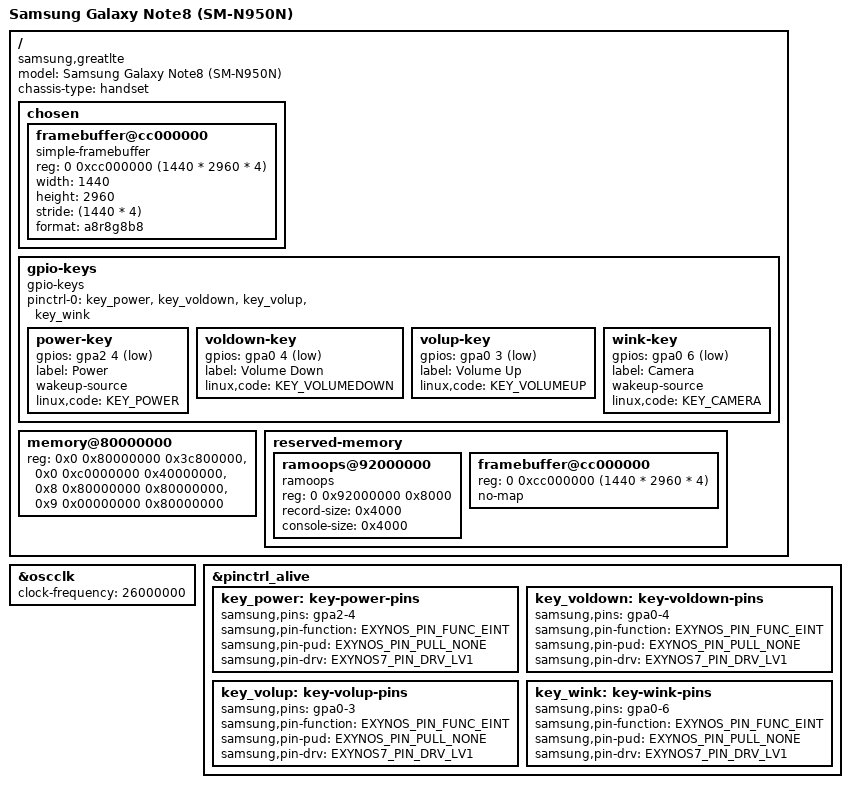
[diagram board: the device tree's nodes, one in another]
// SPDX-License-Identifier: GPL-2.0 OR BSD-3-Clause
/*
 * Samsung Galaxy Note8 (greatlte/SM-N950N) device tree source
 */

/dts-v1/;
#include "exynos8895.dtsi"
#include <dt-bindings/gpio/gpio.h>
#include <dt-bindings/input/input.h>

/ {
	model = "Samsung Galaxy Note8 (SM-N950N)";
	compatible = "samsung,greatlte", "samsung,exynos8895";
	chassis-type = "handset";

	chosen {
		ranges;
		#address-cells = <2>;
		#size-cells = <1>;

		framebuffer@cc000000 {
			compatible = "simple-framebuffer";
			reg = <0 0xcc000000 (1440 * 2960 * 4)>;
			width = <1440>;
			height = <2960>;
			stride = <(1440 * 4)>;
			format = "a8r8g8b8";
		};
	};

	gpio-keys {
		compatible = "gpio-keys";

		pinctrl-0 = <&key_power &key_voldown &key_volup &key_wink>;
		pinctrl-names = "default";

		power-key {
			gpios = <&gpa2 4 GPIO_ACTIVE_LOW>;
			label = "Power";
			wakeup-source;
			linux,code = <KEY_POWER>;
		};

		voldown-key {
			gpios = <&gpa0 4 GPIO_ACTIVE_LOW>;
			label = "Volume Down";
			linux,code = <KEY_VOLUMEDOWN>;
		};

		volup-key {
			gpios = <&gpa0 3 GPIO_ACTIVE_LOW>;
			label = "Volume Up";
			linux,code = <KEY_VOLUMEUP>;
		};

		/* Bixby key, mapped as a camera button for now */
		wink-key {
			gpios = <&gpa0 6 GPIO_ACTIVE_LOW>;
			label = "Camera";
			wakeup-source;
			linux,code = <KEY_CAMERA>;
		};
	};

	memory@80000000 {
		device_type = "memory";
		reg = <0x0 0x80000000 0x3c800000>,
		      <0x0 0xc0000000 0x40000000>,
		      <0x8 0x80000000 0x80000000>,
		      <0x9 0x00000000 0x80000000>;
	};

	reserved-memory {
		ranges;
		#address-cells = <2>;
		#size-cells = <1>;

		ramoops@92000000 {
			compatible = "ramoops";
			reg = <0 0x92000000 0x8000>;
			record-size = <0x4000>;
			console-size = <0x4000>;
		};

		framebuffer@cc000000 {
			reg = <0 0xcc000000 (1440 * 2960 * 4)>;
			no-map;
		};
	};
};

&oscclk {
	clock-frequency = <26000000>;
};

&pinctrl_alive {
	key_power: key-power-pins {
		samsung,pins = "gpa2-4";
		samsung,pin-function = <EXYNOS_PIN_FUNC_EINT>;
		samsung,pin-pud = <EXYNOS_PIN_PULL_NONE>;
		samsung,pin-drv = <EXYNOS7_PIN_DRV_LV1>;
	};

	key_voldown: key-voldown-pins {
		samsung,pins = "gpa0-4";
		samsung,pin-function = <EXYNOS_PIN_FUNC_EINT>;
		samsung,pin-pud = <EXYNOS_PIN_PULL_NONE>;
		samsung,pin-drv = <EXYNOS7_PIN_DRV_LV1>;
	};

	key_volup: key-volup-pins {
		samsung,pins = "gpa0-3";
		samsung,pin-function = <EXYNOS_PIN_FUNC_EINT>;
		samsung,pin-pud = <EXYNOS_PIN_PULL_NONE>;
		samsung,pin-drv = <EXYNOS7_PIN_DRV_LV1>;
	};

	key_wink: key-wink-pins {
		samsung,pins = "gpa0-6";
		samsung,pin-function = <EXYNOS_PIN_FUNC_EINT>;
		samsung,pin-pud = <EXYNOS_PIN_PULL_NONE>;
		samsung,pin-drv = <EXYNOS7_PIN_DRV_LV1>;
	};
};
